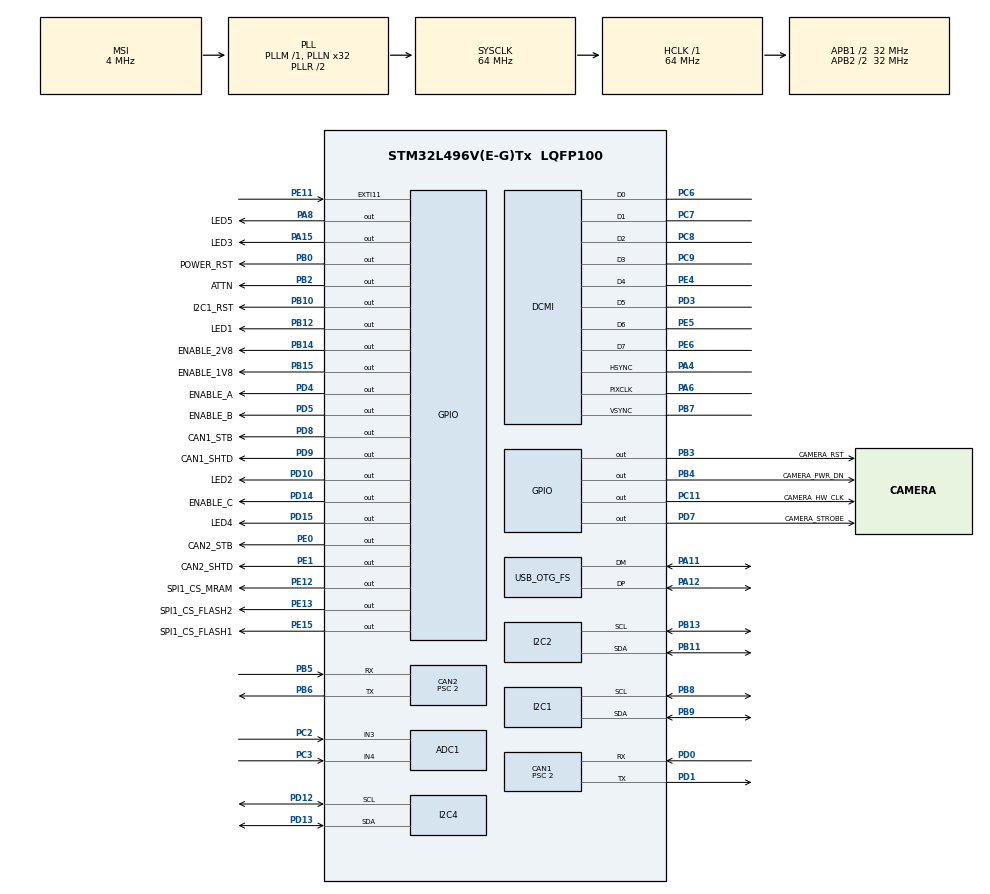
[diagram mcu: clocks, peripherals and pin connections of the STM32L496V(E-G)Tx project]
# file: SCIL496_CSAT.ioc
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ADC1.Channel-1\#ChannelRegularConversion=ADC_CHANNEL_3
ADC1.ClockPrescaler=ADC_CLOCK_ASYNC_DIV128
ADC1.ContinuousConvMode=DISABLE
ADC1.DMAContinuousRequests=DISABLE
ADC1.DiscontinuousConvMode=DISABLE
ADC1.EOCSelection=ADC_EOC_SEQ_CONV
ADC1.NbrOfConversion=1
ADC1.NbrOfConversionFlag=1
ADC1.OffsetNumber-1\#ChannelRegularConversion=ADC_OFFSET_NONE
ADC1.Overrun=ADC_OVR_DATA_PRESERVED
ADC1.Rank-1\#ChannelRegularConversion=1
ADC1.SamplingTime-1\#ChannelRegularConversion=ADC_SAMPLETIME_640CYCLES_5
ADC1.master=1
CAN1.AWUM=ENABLE
CAN1.BS1=CAN_BS1_13TQ
CAN1.BS2=CAN_BS2_2TQ
CAN1.CalculateBaudRate=1000000
CAN1.CalculateTimeBit=1000
CAN1.CalculateTimeQuantum=62.5
CAN1.Prescaler=2
CAN1.TXFP=ENABLE
CAN2.AWUM=ENABLE
CAN2.BS1=CAN_BS1_13TQ
CAN2.BS2=CAN_BS2_2TQ
CAN2.CalculateBaudRate=1000000
CAN2.CalculateTimeBit=1000
CAN2.CalculateTimeQuantum=62.5
CAN2.Prescaler=2
CAN2.TXFP=ENABLE
DCMI.JPEGMode=DCMI_JPEG_DISABLE
Dma.I2C1_RX.0.Direction=DMA_PERIPH_TO_MEMORY
Dma.I2C1_RX.0.Instance=DMA1_Channel7
Dma.I2C1_RX.0.MemDataAlignment=DMA_MDATAALIGN_BYTE
Dma.I2C1_RX.0.MemInc=DMA_MINC_ENABLE
Dma.I2C1_RX.0.Mode=DMA_NORMAL
Dma.I2C1_RX.0.PeriphDataAlignment=DMA_PDATAALIGN_BYTE
Dma.I2C1_RX.0.PeriphInc=DMA_PINC_DISABLE
Dma.I2C1_RX.0.Priority=DMA_PRIORITY_LOW
Dma.I2C1_TX.1.Direction=DMA_MEMORY_TO_PERIPH
Dma.I2C1_TX.1.Instance=DMA1_Channel6
Dma.I2C1_TX.1.MemDataAlignment=DMA_MDATAALIGN_BYTE
Dma.I2C1_TX.1.MemInc=DMA_MINC_ENABLE
Dma.I2C1_TX.1.Mode=DMA_NORMAL
Dma.I2C1_TX.1.PeriphDataAlignment=DMA_PDATAALIGN_BYTE
Dma.I2C1_TX.1.PeriphInc=DMA_PINC_DISABLE
Dma.I2C1_TX.1.Priority=DMA_PRIORITY_LOW
Dma.I2C2_RX.4.Direction=DMA_PERIPH_TO_MEMORY
Dma.I2C2_RX.4.Instance=DMA1_Channel5
Dma.I2C2_RX.4.MemDataAlignment=DMA_MDATAALIGN_BYTE
Dma.I2C2_RX.4.MemInc=DMA_MINC_ENABLE
Dma.I2C2_RX.4.Mode=DMA_NORMAL
Dma.I2C2_RX.4.PeriphDataAlignment=DMA_PDATAALIGN_BYTE
Dma.I2C2_RX.4.PeriphInc=DMA_PINC_DISABLE
Dma.I2C2_RX.4.Priority=DMA_PRIORITY_LOW
Dma.I2C2_TX.5.Direction=DMA_MEMORY_TO_PERIPH
Dma.I2C2_TX.5.Instance=DMA1_Channel4
Dma.I2C2_TX.5.MemDataAlignment=DMA_MDATAALIGN_BYTE
Dma.I2C2_TX.5.MemInc=DMA_MINC_ENABLE
Dma.I2C2_TX.5.Mode=DMA_NORMAL
Dma.I2C2_TX.5.PeriphDataAlignment=DMA_PDATAALIGN_BYTE
Dma.I2C2_TX.5.PeriphInc=DMA_PINC_DISABLE
Dma.I2C2_TX.5.Priority=DMA_PRIORITY_LOW
Dma.I2C4_RX.2.Direction=DMA_PERIPH_TO_MEMORY
Dma.I2C4_RX.2.Instance=DMA2_Channel1
Dma.I2C4_RX.2.MemDataAlignment=DMA_MDATAALIGN_BYTE
Dma.I2C4_RX.2.MemInc=DMA_MINC_ENABLE
Dma.I2C4_RX.2.Mode=DMA_NORMAL
Dma.I2C4_RX.2.PeriphDataAlignment=DMA_PDATAALIGN_BYTE
Dma.I2C4_RX.2.PeriphInc=DMA_PINC_DISABLE
Dma.I2C4_RX.2.Priority=DMA_PRIORITY_LOW
Dma.I2C4_TX.3.Direction=DMA_MEMORY_TO_PERIPH
Dma.I2C4_TX.3.Instance=DMA2_Channel2
Dma.I2C4_TX.3.MemDataAlignment=DMA_MDATAALIGN_BYTE
Dma.I2C4_TX.3.MemInc=DMA_MINC_ENABLE
Dma.I2C4_TX.3.Mode=DMA_NORMAL
Dma.I2C4_TX.3.PeriphDataAlignment=DMA_PDATAALIGN_BYTE
Dma.I2C4_TX.3.PeriphInc=DMA_PINC_DISABLE
Dma.I2C4_TX.3.Priority=DMA_PRIORITY_LOW
Dma.Request0=I2C1_RX
Dma.Request1=I2C1_TX
Dma.Request2=I2C4_RX
Dma.Request3=I2C4_TX
Dma.Request4=I2C2_RX
Dma.Request5=I2C2_TX
I2C1.I2C_Rise_Time=100
I2C1.Speed=100
I2C1.Timing=0x00B07CB4
I2C2.Timing=0x00B07CB4
I2C4.Timing=0x00B07CB4
Mcu.Family=STM32L4
Mcu.Name=STM32L496V(E-G)Tx
Mcu.Package=LQFP100
NVIC.CAN1_RX0_IRQn=true\:0\:0\:false\:false\:true\:true\:true\:true
NVIC.CAN1_RX1_IRQn=true\:0\:0\:false\:false\:true\:true\:true\:true
NVIC.CAN1_SCE_IRQn=true\:0\:0\:false\:false\:true\:true\:true\:true
NVIC.CAN1_TX_IRQn=true\:0\:0\:false\:false\:true\:true\:true\:true
NVIC.CAN2_RX0_IRQn=true\:0\:0\:false\:false\:true\:true\:true\:true
NVIC.CAN2_RX1_IRQn=true\:0\:0\:false\:false\:true\:true\:true\:true
NVIC.CAN2_SCE_IRQn=true\:0\:0\:false\:false\:true\:true\:true\:true
NVIC.DMA1_Channel4_IRQn=true\:0\:0\:false\:false\:true\:false\:true\:true
NVIC.DMA1_Channel5_IRQn=true\:0\:0\:false\:false\:true\:false\:true\:true
NVIC.DMA1_Channel6_IRQn=true\:0\:0\:false\:false\:true\:false\:true\:true
NVIC.DMA1_Channel7_IRQn=true\:0\:0\:false\:false\:true\:false\:true\:true
NVIC.DMA2_Channel1_IRQn=true\:0\:0\:false\:false\:true\:false\:true\:true
NVIC.DMA2_Channel2_IRQn=true\:0\:0\:false\:false\:true\:false\:true\:true
NVIC.OTG_FS_IRQn=true\:0\:0\:false\:false\:true\:false\:true\:true
NVIC.PriorityGroup=NVIC_PRIORITYGROUP_4
PA10.Signal=USART1_RX
PA11.Mode=Device_Only
PA11.Signal=USB_OTG_FS_DM
PA12.Mode=Device_Only
PA12.Signal=USB_OTG_FS_DP
PA15\ (JTDI).GPIO_Label=LED3
PA15\ (JTDI).Signal=GPIO_Output
PA4.Mode=Slave_8_bits_External_Synchro
PA4.Signal=DCMI_HSYNC
PA5.Signal=SPI1_SCK
PA6.Mode=Slave_8_bits_External_Synchro
PA6.Signal=DCMI_PIXCLK
PA7.Signal=SPI1_MOSI
PA8.GPIO_Label=LED5
PA8.Signal=GPIO_Output
PA9.Signal=USART1_TX
PB0.GPIO_Label=POWER_RST
PB0.PinState=GPIO_PIN_RESET
PB0.Signal=GPIO_Output
PB1.Signal=USART3_RTS
PB10.GPIO_Label=I2C1_RST
PB10.GPIO_ModeDefaultOutputPP=GPIO_MODE_OUTPUT_OD
PB10.GPIO_PuPd=GPIO_NOPULL
PB10.PinState=GPIO_PIN_SET
PB10.Signal=GPIO_Output
PB11.Mode=I2C
PB11.Signal=I2C2_SDA
PB12.GPIO_Label=LED1
PB12.Signal=GPIO_Output
PB13.Mode=I2C
PB13.Signal=I2C2_SCL
PB14.GPIO_Label=ENABLE_2V8
PB14.Signal=GPIO_Output
PB15.GPIO_Label=ENABLE_1V8
PB15.Signal=GPIO_Output
PB2.GPIO_Label=ATTN
PB2.PinState=GPIO_PIN_SET
PB2.Signal=GPIO_Output
PB3\ (JTDO/TRACESWO).GPIO_Label=CAMERA_RST
PB3\ (JTDO/TRACESWO).PinState=GPIO_PIN_SET
PB3\ (JTDO/TRACESWO).Signal=GPIO_Output
PB4\ (NJTRST).GPIO_Label=CAMERA_PWR_DN
PB4\ (NJTRST).Signal=GPIO_Output
PB5.Mode=CAN_Activate
PB5.Signal=CAN2_RX
PB6.Mode=CAN_Activate
PB6.Signal=CAN2_TX
PB7.Mode=Slave_8_bits_External_Synchro
PB7.Signal=DCMI_VSYNC
PB8.GPIO_FM8=SYSCFG_FASTMODEPLUS_PB8
PB8.Mode=I2C
PB8.Signal=I2C1_SCL
PB9.GPIO_FM9=SYSCFG_FASTMODEPLUS_PB9
PB9.Mode=I2C
PB9.Signal=I2C1_SDA
PC11.GPIO_Label=CAMERA_HW_CLK
PC11.PinState=GPIO_PIN_SET
PC11.Signal=GPIO_Output
PC2.Signal=SharedAnalog_PC2
PC3.Signal=SharedAnalog_PC3
PC4.Signal=USART3_TX
PC5.Signal=USART3_RX
PC6.Mode=Slave_8_bits_External_Synchro
PC6.Signal=DCMI_D0
PC7.Mode=Slave_8_bits_External_Synchro
PC7.Signal=DCMI_D1
PC8.Mode=Slave_8_bits_External_Synchro
PC8.Signal=DCMI_D2
PC9.Mode=Slave_8_bits_External_Synchro
PC9.Signal=DCMI_D3
PD0.Mode=CAN_Activate
PD0.Signal=CAN1_RX
PD1.Mode=CAN_Activate
PD1.Signal=CAN1_TX
PD10.GPIO_Label=LED2
PD10.Signal=GPIO_Output
PD11.Signal=USART3_CTS
PD12.Mode=I2C
PD12.Signal=I2C4_SCL
PD13.Mode=I2C
PD13.Signal=I2C4_SDA
PD14.GPIO_Label=ENABLE_C
PD14.Signal=GPIO_Output
PD15.GPIO_Label=LED4
PD15.Signal=GPIO_Output
PD3.Mode=Slave_8_bits_External_Synchro
PD3.Signal=DCMI_D5
PD4.GPIO_Label=ENABLE_A
PD4.Signal=GPIO_Output
PD5.GPIO_Label=ENABLE_B
PD5.Signal=GPIO_Output
PD7.GPIO_Label=CAMERA_STROBE
PD7.Signal=GPIO_Output
PD8.GPIO_Label=CAN1_STB
PD8.Signal=GPIO_Output
PD9.GPIO_Label=CAN1_SHTD
PD9.Signal=GPIO_Output
PE0.GPIO_Label=CAN2_STB
PE0.Signal=GPIO_Output
PE1.GPIO_Label=CAN2_SHTD
PE1.Signal=GPIO_Output
PE11.Signal=GPXTI11
PE12.GPIO_Label=SPI1_CS_MRAM
PE12.Signal=GPIO_Output
PE13.GPIO_Label=SPI1_CS_FLASH2
PE13.Signal=GPIO_Output
PE14.Signal=SPI1_MISO
PE15.GPIO_Label=SPI1_CS_FLASH1
PE15.Signal=GPIO_Output
PE4.Mode=Slave_8_bits_External_Synchro
PE4.Signal=DCMI_D4
PE5.Mode=Slave_8_bits_External_Synchro
PE5.Signal=DCMI_D6
PE6.Mode=Slave_8_bits_External_Synchro
PE6.Signal=DCMI_D7
ProjectManager.HeapSize=0x200
ProjectManager.StackSize=0x400
ProjectManager.TargetToolchain=STM32CubeIDE
RCC.ADCFreq_Value=64000000
RCC.AHBFreq_Value=64000000
RCC.APB1CLKDivider=RCC_HCLK_DIV2
RCC.APB1Freq_Value=32000000
RCC.APB1TimFreq_Value=64000000
RCC.APB2CLKDivider=RCC_HCLK_DIV2
RCC.APB2Freq_Value=32000000
RCC.APB2TimFreq_Value=64000000
RCC.CK48CLockSelection=RCC_USBCLKSOURCE_HSI48
RCC.CortexFreq_Value=64000000
RCC.HCLKFreq_Value=64000000
RCC.HSE_VALUE=8000000
RCC.HSI48_VALUE=48000000
RCC.HSI_VALUE=16000000
RCC.LSE_VALUE=32768
RCC.MSI_VALUE=4000000
RCC.PLLN=32
RCC.PLLSAI1N=32
RCC.SYSCLKFreq_VALUE=64000000
RCC.SYSCLKSource=RCC_SYSCLKSOURCE_PLLCLK
RCC.USBFreq_Value=48000000
RCC.VCOOutputFreq_Value=128000000
SH.SharedAnalog_PC2.0=GPIO_Analog
SH.SharedAnalog_PC2.1=ADC1_IN3,IN3-Single-Ended
SH.SharedAnalog_PC3.0=GPIO_Analog
SH.SharedAnalog_PC3.1=ADC1_IN4,IN4-Single-Ended
USB_DEVICE.CLASS_NAME_FS=CDC
USB_DEVICE.VirtualMode=Cdc
USB_DEVICE.VirtualModeFS=Cdc_FS
USB_OTG_FS.VirtualMode=Device_Only
VP_RTC_VS_RTC_Activate.Mode=RTC_Enabled
VP_USB_DEVICE_VS_USB_DEVICE_CDC_FS.Mode=CDC_FS
board=custom

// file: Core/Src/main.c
/* USER CODE BEGIN Header */
/**
  ******************************************************************************
  * @file           : main.c
  * @brief          : Main program body
  ******************************************************************************
  * @attention
  *
  * Copyright (c) 2025 STMicroelectronics.
  * All rights reserved.
  *
  * This software is licensed under terms that can be found in the LICENSE file
  * in the root directory of this software component.
  * If no LICENSE file comes with this software, it is provided AS-IS.
  *
  ******************************************************************************
  */
/* USER CODE END Header */
#include "main.h"
#include "usb_device.h"

/* USER CODE BEGIN Includes */
#include "cppmain.h"
#include "usbd_cdc_if.h"
/* USER CODE END Includes */

ADC_HandleTypeDef hadc1;

CAN_HandleTypeDef hcan1;
CAN_HandleTypeDef hcan2;

DCMI_HandleTypeDef hdcmi;

I2C_HandleTypeDef hi2c1;
I2C_HandleTypeDef hi2c2;
I2C_HandleTypeDef hi2c4;
DMA_HandleTypeDef hdma_i2c1_rx;
DMA_HandleTypeDef hdma_i2c1_tx;
DMA_HandleTypeDef hdma_i2c2_rx;
DMA_HandleTypeDef hdma_i2c2_tx;
DMA_HandleTypeDef hdma_i2c4_rx;
DMA_HandleTypeDef hdma_i2c4_tx;

RTC_HandleTypeDef hrtc;

void SystemClock_Config(void);
static void MX_GPIO_Init(void);
static void MX_DMA_Init(void);
static void MX_CAN1_Init(void);
static void MX_CAN2_Init(void);
static void MX_I2C4_Init(void);
static void MX_DCMI_Init(void);
static void MX_I2C1_Init(void);
static void MX_I2C2_Init(void);
static void MX_RTC_Init(void);
static void MX_ADC1_Init(void);

/* USER CODE BEGIN 0 */
extern int getentropy(void* buffer, size_t length) {
    (void)buffer;
    (void)length;
    return -1; // ENOSYS: Function not implemented
}
/* USER CODE END 0 */

int main(void)
{

  /* MCU Configuration--------------------------------------------------------*/

  /* Reset of all peripherals, Initializes the Flash interface and the Systick. */
  HAL_Init();

  /* Configure the system clock */
  SystemClock_Config();

  /* Initialize all configured peripherals */
  MX_GPIO_Init();
  MX_DMA_Init();
  MX_CAN1_Init();
  MX_CAN2_Init();
  MX_USB_DEVICE_Init();
  MX_I2C4_Init();
  MX_DCMI_Init();
  MX_I2C1_Init();
  MX_I2C2_Init();
  MX_RTC_Init();
  MX_ADC1_Init();
  /* USER CODE BEGIN 2 */
  cppmain();

  /* USER CODE END 2 */

  /* Infinite loop */
  while (1)
  {

  }
}

void SystemClock_Config(void)
{
  RCC_OscInitTypeDef RCC_OscInitStruct = {0};
  RCC_ClkInitTypeDef RCC_ClkInitStruct = {0};

  /** Configure the main internal regulator output voltage
  */
  if (HAL_PWREx_ControlVoltageScaling(PWR_REGULATOR_VOLTAGE_SCALE1) != HAL_OK)
  {
    Error_Handler();
  }

  /** Initializes the RCC Oscillators according to the specified parameters
  * in the RCC_OscInitTypeDef structure.
  */
  RCC_OscInitStruct.OscillatorType = RCC_OSCILLATORTYPE_HSI48|RCC_OSCILLATORTYPE_LSI
                              |RCC_OSCILLATORTYPE_MSI;
  RCC_OscInitStruct.HSI48State = RCC_HSI48_ON;
  RCC_OscInitStruct.LSIState = RCC_LSI_ON;
  RCC_OscInitStruct.MSIState = RCC_MSI_ON;
  RCC_OscInitStruct.MSICalibrationValue = 0;
  RCC_OscInitStruct.MSIClockRange = RCC_MSIRANGE_6;
  RCC_OscInitStruct.PLL.PLLState = RCC_PLL_ON;
  RCC_OscInitStruct.PLL.PLLSource = RCC_PLLSOURCE_MSI;
  RCC_OscInitStruct.PLL.PLLM = 1;
  RCC_OscInitStruct.PLL.PLLN = 32;
  RCC_OscInitStruct.PLL.PLLP = RCC_PLLP_DIV2;
  RCC_OscInitStruct.PLL.PLLQ = RCC_PLLQ_DIV2;
  RCC_OscInitStruct.PLL.PLLR = RCC_PLLR_DIV2;
  if (HAL_RCC_OscConfig(&RCC_OscInitStruct) != HAL_OK)
  {
    Error_Handler();
  }

  /** Initializes the CPU, AHB and APB buses clocks
  */
  RCC_ClkInitStruct.ClockType = RCC_CLOCKTYPE_HCLK|RCC_CLOCKTYPE_SYSCLK
                              |RCC_CLOCKTYPE_PCLK1|RCC_CLOCKTYPE_PCLK2;
  RCC_ClkInitStruct.SYSCLKSource = RCC_SYSCLKSOURCE_PLLCLK;
  RCC_ClkInitStruct.AHBCLKDivider = RCC_SYSCLK_DIV1;
  RCC_ClkInitStruct.APB1CLKDivider = RCC_HCLK_DIV2;
  RCC_ClkInitStruct.APB2CLKDivider = RCC_HCLK_DIV2;

  if (HAL_RCC_ClockConfig(&RCC_ClkInitStruct, FLASH_LATENCY_3) != HAL_OK)
  {
    Error_Handler();
  }
}

static void MX_ADC1_Init(void)
{

  /* USER CODE BEGIN ADC1_Init 0 */
	GPIO_InitTypeDef GPIO_InitStruct = {0};
	GPIO_InitStruct.Pin = GPIO_PIN_2 | GPIO_PIN_3;
	GPIO_InitStruct.Mode = GPIO_MODE_ANALOG;
	GPIO_InitStruct.Pull = GPIO_NOPULL;
	HAL_GPIO_Init(GPIOC, &GPIO_InitStruct);

  /* USER CODE END ADC1_Init 0 */

  ADC_MultiModeTypeDef multimode = {0};
  ADC_ChannelConfTypeDef sConfig = {0};

  /** Common config
  */
  hadc1.Instance = ADC1;
  hadc1.Init.ClockPrescaler = ADC_CLOCK_ASYNC_DIV128;
  hadc1.Init.Resolution = ADC_RESOLUTION_12B;
  hadc1.Init.DataAlign = ADC_DATAALIGN_RIGHT;
  hadc1.Init.ScanConvMode = ADC_SCAN_DISABLE;
  hadc1.Init.EOCSelection = ADC_EOC_SEQ_CONV;
  hadc1.Init.LowPowerAutoWait = DISABLE;
  hadc1.Init.ContinuousConvMode = DISABLE;
  hadc1.Init.NbrOfConversion = 1;
  hadc1.Init.DiscontinuousConvMode = DISABLE;
  hadc1.Init.ExternalTrigConv = ADC_SOFTWARE_START;
  hadc1.Init.ExternalTrigConvEdge = ADC_EXTERNALTRIGCONVEDGE_NONE;
  hadc1.Init.DMAContinuousRequests = DISABLE;
  hadc1.Init.Overrun = ADC_OVR_DATA_PRESERVED;
  hadc1.Init.OversamplingMode = DISABLE;
  if (HAL_ADC_Init(&hadc1) != HAL_OK)
  {
    Error_Handler();
  }

  /** Configure the ADC multi-mode
  */
  multimode.Mode = ADC_MODE_INDEPENDENT;
  if (HAL_ADCEx_MultiModeConfigChannel(&hadc1, &multimode) != HAL_OK)
  {
    Error_Handler();
  }

  /** Configure Regular Channel
  */
  sConfig.Channel = ADC_CHANNEL_3;
  sConfig.Rank = ADC_REGULAR_RANK_1;
  sConfig.SamplingTime = ADC_SAMPLETIME_640CYCLES_5;
  sConfig.SingleDiff = ADC_SINGLE_ENDED;
  sConfig.OffsetNumber = ADC_OFFSET_NONE;
  sConfig.Offset = 0;
  if (HAL_ADC_ConfigChannel(&hadc1, &sConfig) != HAL_OK)
  {
    Error_Handler();
  }
  /* USER CODE BEGIN ADC1_Init 2 */
	HAL_ADCEx_Calibration_Start(&hadc1, ADC_SINGLE_ENDED);
  /* USER CODE END ADC1_Init 2 */

}

static void MX_CAN1_Init(void)
{

  hcan1.Instance = CAN1;
  hcan1.Init.Prescaler = 2;
  hcan1.Init.Mode = CAN_MODE_NORMAL;
  hcan1.Init.SyncJumpWidth = CAN_SJW_1TQ;
  hcan1.Init.TimeSeg1 = CAN_BS1_13TQ;
  hcan1.Init.TimeSeg2 = CAN_BS2_2TQ;
  hcan1.Init.TimeTriggeredMode = DISABLE;
  hcan1.Init.AutoBusOff = DISABLE;
  hcan1.Init.AutoWakeUp = ENABLE;
  hcan1.Init.AutoRetransmission = DISABLE;
  hcan1.Init.ReceiveFifoLocked = DISABLE;
  hcan1.Init.TransmitFifoPriority = ENABLE;
  if (HAL_CAN_Init(&hcan1) != HAL_OK)
  {
    Error_Handler();
  }

}

static void MX_CAN2_Init(void)
{

  hcan2.Instance = CAN2;
  hcan2.Init.Prescaler = 2;
  hcan2.Init.Mode = CAN_MODE_NORMAL;
  hcan2.Init.SyncJumpWidth = CAN_SJW_1TQ;
  hcan2.Init.TimeSeg1 = CAN_BS1_13TQ;
  hcan2.Init.TimeSeg2 = CAN_BS2_2TQ;
  hcan2.Init.TimeTriggeredMode = DISABLE;
  hcan2.Init.AutoBusOff = DISABLE;
  hcan2.Init.AutoWakeUp = ENABLE;
  hcan2.Init.AutoRetransmission = DISABLE;
  hcan2.Init.ReceiveFifoLocked = DISABLE;
  hcan2.Init.TransmitFifoPriority = ENABLE;
  if (HAL_CAN_Init(&hcan2) != HAL_OK)
  {
    Error_Handler();
  }

}

static void MX_DCMI_Init(void)
{

  hdcmi.Instance = DCMI;
  hdcmi.Init.SynchroMode = DCMI_SYNCHRO_HARDWARE;
  hdcmi.Init.PCKPolarity = DCMI_PCKPOLARITY_FALLING;
  hdcmi.Init.VSPolarity = DCMI_VSPOLARITY_LOW;
  hdcmi.Init.HSPolarity = DCMI_HSPOLARITY_LOW;
  hdcmi.Init.CaptureRate = DCMI_CR_ALL_FRAME;
  hdcmi.Init.ExtendedDataMode = DCMI_EXTEND_DATA_8B;
  hdcmi.Init.JPEGMode = DCMI_JPEG_DISABLE;
  hdcmi.Init.ByteSelectMode = DCMI_BSM_ALL;
  hdcmi.Init.ByteSelectStart = DCMI_OEBS_ODD;
  hdcmi.Init.LineSelectMode = DCMI_LSM_ALL;
  hdcmi.Init.LineSelectStart = DCMI_OELS_ODD;
  if (HAL_DCMI_Init(&hdcmi) != HAL_OK)
  {
    Error_Handler();
  }

}

static void MX_I2C1_Init(void)
{

  hi2c1.Instance = I2C1;
  hi2c1.Init.Timing = 0x00B07CB4;
  hi2c1.Init.OwnAddress1 = 0;
  hi2c1.Init.AddressingMode = I2C_ADDRESSINGMODE_7BIT;
  hi2c1.Init.DualAddressMode = I2C_DUALADDRESS_DISABLE;
  hi2c1.Init.OwnAddress2 = 0;
  hi2c1.Init.OwnAddress2Masks = I2C_OA2_NOMASK;
  hi2c1.Init.GeneralCallMode = I2C_GENERALCALL_DISABLE;
  hi2c1.Init.NoStretchMode = I2C_NOSTRETCH_DISABLE;
  if (HAL_I2C_Init(&hi2c1) != HAL_OK)
  {
    Error_Handler();
  }

  /** Configure Analogue filter
  */
  if (HAL_I2CEx_ConfigAnalogFilter(&hi2c1, I2C_ANALOGFILTER_ENABLE) != HAL_OK)
  {
    Error_Handler();
  }

  /** Configure Digital filter
  */
  if (HAL_I2CEx_ConfigDigitalFilter(&hi2c1, 0) != HAL_OK)
  {
    Error_Handler();
  }

}

static void MX_I2C2_Init(void)
{

  hi2c2.Instance = I2C2;
  hi2c2.Init.Timing = 0x00B07CB4;
  hi2c2.Init.OwnAddress1 = 0;
  hi2c2.Init.AddressingMode = I2C_ADDRESSINGMODE_7BIT;
  hi2c2.Init.DualAddressMode = I2C_DUALADDRESS_DISABLE;
  hi2c2.Init.OwnAddress2 = 0;
  hi2c2.Init.OwnAddress2Masks = I2C_OA2_NOMASK;
  hi2c2.Init.GeneralCallMode = I2C_GENERALCALL_DISABLE;
  hi2c2.Init.NoStretchMode = I2C_NOSTRETCH_DISABLE;
  if (HAL_I2C_Init(&hi2c2) != HAL_OK)
  {
    Error_Handler();
  }

  /** Configure Analogue filter
  */
  if (HAL_I2CEx_ConfigAnalogFilter(&hi2c2, I2C_ANALOGFILTER_ENABLE) != HAL_OK)
  {
    Error_Handler();
  }

  /** Configure Digital filter
  */
  if (HAL_I2CEx_ConfigDigitalFilter(&hi2c2, 0) != HAL_OK)
  {
    Error_Handler();
  }

}

static void MX_I2C4_Init(void)
{

  hi2c4.Instance = I2C4;
  hi2c4.Init.Timing = 0x00B07CB4;
  hi2c4.Init.OwnAddress1 = 0;
  hi2c4.Init.AddressingMode = I2C_ADDRESSINGMODE_7BIT;
  hi2c4.Init.DualAddressMode = I2C_DUALADDRESS_DISABLE;
  hi2c4.Init.OwnAddress2 = 0;
  hi2c4.Init.OwnAddress2Masks = I2C_OA2_NOMASK;
  hi2c4.Init.GeneralCallMode = I2C_GENERALCALL_DISABLE;
  hi2c4.Init.NoStretchMode = I2C_NOSTRETCH_DISABLE;
  if (HAL_I2C_Init(&hi2c4) != HAL_OK)
  {
    Error_Handler();
  }

  /** Configure Analogue filter
  */
  if (HAL_I2CEx_ConfigAnalogFilter(&hi2c4, I2C_ANALOGFILTER_ENABLE) != HAL_OK)
  {
    Error_Handler();
  }

  /** Configure Digital filter
  */
  if (HAL_I2CEx_ConfigDigitalFilter(&hi2c4, 0) != HAL_OK)
  {
    Error_Handler();
  }

}

static void MX_RTC_Init(void)
{

  /** Initialize RTC Only
  */
  hrtc.Instance = RTC;
  hrtc.Init.HourFormat = RTC_HOURFORMAT_24;
  hrtc.Init.AsynchPrediv = 127;
  hrtc.Init.SynchPrediv = 255;
  hrtc.Init.OutPut = RTC_OUTPUT_DISABLE;
  hrtc.Init.OutPutRemap = RTC_OUTPUT_REMAP_NONE;
  hrtc.Init.OutPutPolarity = RTC_OUTPUT_POLARITY_HIGH;
  hrtc.Init.OutPutType = RTC_OUTPUT_TYPE_OPENDRAIN;
  if (HAL_RTC_Init(&hrtc) != HAL_OK)
  {
    Error_Handler();
  }

}

static void MX_DMA_Init(void)
{

  /* DMA controller clock enable */
  __HAL_RCC_DMA1_CLK_ENABLE();
  __HAL_RCC_DMA2_CLK_ENABLE();

  /* DMA interrupt init */
  /* DMA1_Channel4_IRQn interrupt configuration */
  HAL_NVIC_SetPriority(DMA1_Channel4_IRQn, 0, 0);
  HAL_NVIC_EnableIRQ(DMA1_Channel4_IRQn);
  /* DMA1_Channel5_IRQn interrupt configuration */
  HAL_NVIC_SetPriority(DMA1_Channel5_IRQn, 0, 0);
  HAL_NVIC_EnableIRQ(DMA1_Channel5_IRQn);
  /* DMA1_Channel6_IRQn interrupt configuration */
  HAL_NVIC_SetPriority(DMA1_Channel6_IRQn, 0, 0);
  HAL_NVIC_EnableIRQ(DMA1_Channel6_IRQn);
  /* DMA1_Channel7_IRQn interrupt configuration */
  HAL_NVIC_SetPriority(DMA1_Channel7_IRQn, 0, 0);
  HAL_NVIC_EnableIRQ(DMA1_Channel7_IRQn);
  /* DMA2_Channel1_IRQn interrupt configuration */
  HAL_NVIC_SetPriority(DMA2_Channel1_IRQn, 0, 0);
  HAL_NVIC_EnableIRQ(DMA2_Channel1_IRQn);
  /* DMA2_Channel2_IRQn interrupt configuration */
  HAL_NVIC_SetPriority(DMA2_Channel2_IRQn, 0, 0);
  HAL_NVIC_EnableIRQ(DMA2_Channel2_IRQn);

}

static void MX_GPIO_Init(void)
{
  GPIO_InitTypeDef GPIO_InitStruct = {0};

  /* GPIO Ports Clock Enable */
  __HAL_RCC_GPIOE_CLK_ENABLE();
  __HAL_RCC_GPIOC_CLK_ENABLE();
  __HAL_RCC_GPIOA_CLK_ENABLE();
  __HAL_RCC_GPIOB_CLK_ENABLE();
  __HAL_RCC_GPIOD_CLK_ENABLE();

  /*Configure GPIO pin Output Level */
  HAL_GPIO_WritePin(GPIOB, POWER_RST_Pin|LED1_Pin|ENABLE_2V8_Pin|ENABLE_1V8_Pin
                          |CAMERA_PWR_DN_Pin, GPIO_PIN_RESET);

  /*Configure GPIO pin Output Level */
  HAL_GPIO_WritePin(GPIOB, ATTN_Pin|I2C1_RST_Pin|CAMERA_RST_Pin, GPIO_PIN_SET);

  /*Configure GPIO pin Output Level */
  HAL_GPIO_WritePin(GPIOE, SPI1_CS_MRAM_Pin|SPI1_CS_FLASH2_Pin|SPI1_CS_FLASH1_Pin|CAN2_STB_Pin
                          |CAN2_SHTD_Pin, GPIO_PIN_RESET);

  /*Configure GPIO pin Output Level */
  HAL_GPIO_WritePin(GPIOD, CAN1_STB_Pin|CAN1_SHTD_Pin|LED2_Pin|ENABLE_C_Pin
                          |LED4_Pin|ENABLE_A_Pin|ENABLE_B_Pin|CAMERA_STROBE_Pin, GPIO_PIN_RESET);

  /*Configure GPIO pin Output Level */
  HAL_GPIO_WritePin(GPIOA, LED5_Pin|LED3_Pin, GPIO_PIN_RESET);

  /*Configure GPIO pin Output Level */
  HAL_GPIO_WritePin(CAMERA_HW_CLK_GPIO_Port, CAMERA_HW_CLK_Pin, GPIO_PIN_SET);

  /*Configure GPIO pins : PA5 PA7 */
  GPIO_InitStruct.Pin = GPIO_PIN_5|GPIO_PIN_7;
  GPIO_InitStruct.Mode = GPIO_MODE_AF_PP;
  GPIO_InitStruct.Pull = GPIO_NOPULL;
  GPIO_InitStruct.Speed = GPIO_SPEED_FREQ_VERY_HIGH;
  GPIO_InitStruct.Alternate = GPIO_AF5_SPI1;
  HAL_GPIO_Init(GPIOA, &GPIO_InitStruct);

  /*Configure GPIO pins : PC4 PC5 */
  GPIO_InitStruct.Pin = GPIO_PIN_4|GPIO_PIN_5;
  GPIO_InitStruct.Mode = GPIO_MODE_AF_PP;
  GPIO_InitStruct.Pull = GPIO_NOPULL;
  GPIO_InitStruct.Speed = GPIO_SPEED_FREQ_VERY_HIGH;
  GPIO_InitStruct.Alternate = GPIO_AF7_USART3;
  HAL_GPIO_Init(GPIOC, &GPIO_InitStruct);

  /*Configure GPIO pins : POWER_RST_Pin ATTN_Pin LED1_Pin ENABLE_2V8_Pin
                           ENABLE_1V8_Pin CAMERA_RST_Pin CAMERA_PWR_DN_Pin */
  GPIO_InitStruct.Pin = POWER_RST_Pin|ATTN_Pin|LED1_Pin|ENABLE_2V8_Pin
                          |ENABLE_1V8_Pin|CAMERA_RST_Pin|CAMERA_PWR_DN_Pin;
  GPIO_InitStruct.Mode = GPIO_MODE_OUTPUT_PP;
  GPIO_InitStruct.Pull = GPIO_NOPULL;
  GPIO_InitStruct.Speed = GPIO_SPEED_FREQ_LOW;
  HAL_GPIO_Init(GPIOB, &GPIO_InitStruct);

  /*Configure GPIO pin : PB1 */
  GPIO_InitStruct.Pin = GPIO_PIN_1;
  GPIO_InitStruct.Mode = GPIO_MODE_AF_PP;
  GPIO_InitStruct.Pull = GPIO_NOPULL;
  GPIO_InitStruct.Speed = GPIO_SPEED_FREQ_VERY_HIGH;
  GPIO_InitStruct.Alternate = GPIO_AF7_USART3;
  HAL_GPIO_Init(GPIOB, &GPIO_InitStruct);

  /*Configure GPIO pin : PE11 */
  GPIO_InitStruct.Pin = GPIO_PIN_11;
  GPIO_InitStruct.Mode = GPIO_MODE_IT_RISING;
  GPIO_InitStruct.Pull = GPIO_NOPULL;
  HAL_GPIO_Init(GPIOE, &GPIO_InitStruct);

  /*Configure GPIO pins : SPI1_CS_MRAM_Pin SPI1_CS_FLASH2_Pin SPI1_CS_FLASH1_Pin CAN2_STB_Pin
                           CAN2_SHTD_Pin */
  GPIO_InitStruct.Pin = SPI1_CS_MRAM_Pin|SPI1_CS_FLASH2_Pin|SPI1_CS_FLASH1_Pin|CAN2_STB_Pin
                          |CAN2_SHTD_Pin;
  GPIO_InitStruct.Mode = GPIO_MODE_OUTPUT_PP;
  GPIO_InitStruct.Pull = GPIO_NOPULL;
  GPIO_InitStruct.Speed = GPIO_SPEED_FREQ_LOW;
  HAL_GPIO_Init(GPIOE, &GPIO_InitStruct);

  /*Configure GPIO pin : PE14 */
  GPIO_InitStruct.Pin = GPIO_PIN_14;
  GPIO_InitStruct.Mode = GPIO_MODE_AF_PP;
  GPIO_InitStruct.Pull = GPIO_NOPULL;
  GPIO_InitStruct.Speed = GPIO_SPEED_FREQ_VERY_HIGH;
  GPIO_InitStruct.Alternate = GPIO_AF5_SPI1;
  HAL_GPIO_Init(GPIOE, &GPIO_InitStruct);

  /*Configure GPIO pin : I2C1_RST_Pin */
  GPIO_InitStruct.Pin = I2C1_RST_Pin;
  GPIO_InitStruct.Mode = GPIO_MODE_OUTPUT_OD;
  GPIO_InitStruct.Pull = GPIO_NOPULL;
  GPIO_InitStruct.Speed = GPIO_SPEED_FREQ_LOW;
  HAL_GPIO_Init(I2C1_RST_GPIO_Port, &GPIO_InitStruct);

  /*Configure GPIO pins : CAN1_STB_Pin CAN1_SHTD_Pin LED2_Pin ENABLE_C_Pin
                           LED4_Pin ENABLE_A_Pin ENABLE_B_Pin CAMERA_STROBE_Pin */
  GPIO_InitStruct.Pin = CAN1_STB_Pin|CAN1_SHTD_Pin|LED2_Pin|ENABLE_C_Pin
                          |LED4_Pin|ENABLE_A_Pin|ENABLE_B_Pin|CAMERA_STROBE_Pin;
  GPIO_InitStruct.Mode = GPIO_MODE_OUTPUT_PP;
  GPIO_InitStruct.Pull = GPIO_NOPULL;
  GPIO_InitStruct.Speed = GPIO_SPEED_FREQ_LOW;
  HAL_GPIO_Init(GPIOD, &GPIO_InitStruct);

  /*Configure GPIO pin : PD11 */
  GPIO_InitStruct.Pin = GPIO_PIN_11;
  GPIO_InitStruct.Mode = GPIO_MODE_AF_PP;
  GPIO_InitStruct.Pull = GPIO_NOPULL;
  GPIO_InitStruct.Speed = GPIO_SPEED_FREQ_VERY_HIGH;
  GPIO_InitStruct.Alternate = GPIO_AF7_USART3;
  HAL_GPIO_Init(GPIOD, &GPIO_InitStruct);

  /*Configure GPIO pins : LED5_Pin LED3_Pin */
  GPIO_InitStruct.Pin = LED5_Pin|LED3_Pin;
  GPIO_InitStruct.Mode = GPIO_MODE_OUTPUT_PP;
  GPIO_InitStruct.Pull = GPIO_NOPULL;
  GPIO_InitStruct.Speed = GPIO_SPEED_FREQ_LOW;
  HAL_GPIO_Init(GPIOA, &GPIO_InitStruct);

  /*Configure GPIO pins : PA9 PA10 */
  GPIO_InitStruct.Pin = GPIO_PIN_9|GPIO_PIN_10;
  GPIO_InitStruct.Mode = GPIO_MODE_AF_PP;
  GPIO_InitStruct.Pull = GPIO_NOPULL;
  GPIO_InitStruct.Speed = GPIO_SPEED_FREQ_VERY_HIGH;
  GPIO_InitStruct.Alternate = GPIO_AF7_USART1;
  HAL_GPIO_Init(GPIOA, &GPIO_InitStruct);

  /*Configure GPIO pin : CAMERA_HW_CLK_Pin */
  GPIO_InitStruct.Pin = CAMERA_HW_CLK_Pin;
  GPIO_InitStruct.Mode = GPIO_MODE_OUTPUT_PP;
  GPIO_InitStruct.Pull = GPIO_NOPULL;
  GPIO_InitStruct.Speed = GPIO_SPEED_FREQ_LOW;
  HAL_GPIO_Init(CAMERA_HW_CLK_GPIO_Port, &GPIO_InitStruct);

}

void Error_Handler(void)
{
  __disable_irq();
  while (1)
  {
  }
}
